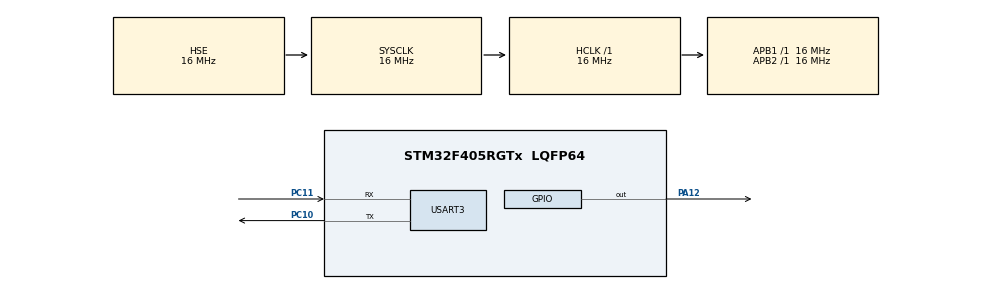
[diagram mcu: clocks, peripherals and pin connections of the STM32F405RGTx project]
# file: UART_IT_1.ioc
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Mcu.Family=STM32F4
Mcu.Name=STM32F405RGTx
Mcu.Package=LQFP64
NVIC.PriorityGroup=NVIC_PRIORITYGROUP_4
NVIC.USART3_IRQn=true\:0\:0\:false\:false\:true\:true\:true\:true
PA12.Signal=GPIO_Output
PA13.Mode=Serial_Wire
PA13.Signal=SYS_JTMS-SWDIO
PA14.Mode=Serial_Wire
PA14.Signal=SYS_JTCK-SWCLK
PC10.Mode=Asynchronous
PC10.Signal=USART3_TX
PC11.Mode=Asynchronous
PC11.Signal=USART3_RX
PH0-OSC_IN.Mode=HSE-External-Oscillator
PH0-OSC_IN.Signal=RCC_OSC_IN
PH1-OSC_OUT.Mode=HSE-External-Oscillator
PH1-OSC_OUT.Signal=RCC_OSC_OUT
ProjectManager.HeapSize=0x200
ProjectManager.StackSize=0x400
ProjectManager.TargetToolchain=MDK-ARM V5.32
RCC.AHBFreq_Value=16000000
RCC.APB1Freq_Value=16000000
RCC.APB2Freq_Value=16000000
RCC.CortexFreq_Value=16000000
RCC.HSE_VALUE=16000000
RCC.HSI_VALUE=16000000
RCC.LSE_VALUE=32768
RCC.PLLSourceVirtual=RCC_PLLSOURCE_HSE
RCC.SYSCLKFreq_VALUE=16000000
RCC.SYSCLKSource=RCC_SYSCLKSOURCE_HSE
RCC.VCOOutputFreq_Value=192000000
USART3.VirtualMode=VM_ASYNC
board=custom

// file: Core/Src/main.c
/* USER CODE BEGIN Header */
/**
  ******************************************************************************
  * @file           : main.c
  * @brief          : Main program body
  ******************************************************************************
  * @attention
  *
  * Copyright (c) 2023 STMicroelectronics.
  * All rights reserved.
  *
  * This software is licensed under terms that can be found in the LICENSE file
  * in the root directory of this software component.
  * If no LICENSE file comes with this software, it is provided AS-IS.
  *
  ******************************************************************************
  */
/* USER CODE END Header */
#include "main.h"

/* USER CODE BEGIN PM */
#define LED1_ON HAL_GPIO_TogglePin(GPIOA,GPIO_PIN_12)
/* USER CODE END PM */

UART_HandleTypeDef huart3;

void SystemClock_Config(void);
static void MX_GPIO_Init(void);
static void MX_USART3_UART_Init(void);

/* USER CODE BEGIN 0 */
  uint8_t data[2000];
	uint8_t count;
/* USER CODE END 0 */

	void HAL_UART_TxCpltCallback(UART_HandleTypeDef *huart)
{

}
int main(void)
{
  /* USER CODE BEGIN 1 */
{
for (int i=0; i<2000; i++)
 {
   data[i] = 'x';
 }
  /* USER CODE END 1 */

  /* MCU Configuration--------------------------------------------------------*/

  /* Reset of all peripherals, Initializes the Flash interface and the Systick. */
  HAL_Init();

  /* Configure the system clock */
  SystemClock_Config();

  /* Initialize all configured peripherals */
  MX_GPIO_Init();
  MX_USART3_UART_Init();

  /* Infinite loop */
  while (1)
  {

	LED1_ON;
  HAL_Delay (1000);

  count++;

  if ((count%20) == 0)
   {
     HAL_UART_Transmit_IT(&huart3, data, sizeof (data));
   }
  }
}
}

void SystemClock_Config(void)
{
  RCC_OscInitTypeDef RCC_OscInitStruct = {0};
  RCC_ClkInitTypeDef RCC_ClkInitStruct = {0};

  /** Configure the main internal regulator output voltage
  */
  __HAL_RCC_PWR_CLK_ENABLE();
  __HAL_PWR_VOLTAGESCALING_CONFIG(PWR_REGULATOR_VOLTAGE_SCALE1);

  /** Initializes the RCC Oscillators according to the specified parameters
  * in the RCC_OscInitTypeDef structure.
  */
  RCC_OscInitStruct.OscillatorType = RCC_OSCILLATORTYPE_HSE;
  RCC_OscInitStruct.HSEState = RCC_HSE_ON;
  RCC_OscInitStruct.PLL.PLLState = RCC_PLL_NONE;
  if (HAL_RCC_OscConfig(&RCC_OscInitStruct) != HAL_OK)
  {
    Error_Handler();
  }

  /** Initializes the CPU, AHB and APB buses clocks
  */
  RCC_ClkInitStruct.ClockType = RCC_CLOCKTYPE_HCLK|RCC_CLOCKTYPE_SYSCLK
                              |RCC_CLOCKTYPE_PCLK1|RCC_CLOCKTYPE_PCLK2;
  RCC_ClkInitStruct.SYSCLKSource = RCC_SYSCLKSOURCE_HSE;
  RCC_ClkInitStruct.AHBCLKDivider = RCC_SYSCLK_DIV1;
  RCC_ClkInitStruct.APB1CLKDivider = RCC_HCLK_DIV1;
  RCC_ClkInitStruct.APB2CLKDivider = RCC_HCLK_DIV1;

  if (HAL_RCC_ClockConfig(&RCC_ClkInitStruct, FLASH_LATENCY_0) != HAL_OK)
  {
    Error_Handler();
  }
}

static void MX_USART3_UART_Init(void)
{

  huart3.Instance = USART3;
  huart3.Init.BaudRate = 115200;
  huart3.Init.WordLength = UART_WORDLENGTH_8B;
  huart3.Init.StopBits = UART_STOPBITS_1;
  huart3.Init.Parity = UART_PARITY_NONE;
  huart3.Init.Mode = UART_MODE_TX_RX;
  huart3.Init.HwFlowCtl = UART_HWCONTROL_NONE;
  huart3.Init.OverSampling = UART_OVERSAMPLING_16;
  if (HAL_UART_Init(&huart3) != HAL_OK)
  {
    Error_Handler();
  }

}

static void MX_GPIO_Init(void)
{
  GPIO_InitTypeDef GPIO_InitStruct = {0};

  /* GPIO Ports Clock Enable */
  __HAL_RCC_GPIOH_CLK_ENABLE();
  __HAL_RCC_GPIOA_CLK_ENABLE();
  __HAL_RCC_GPIOC_CLK_ENABLE();

  /*Configure GPIO pin Output Level */
  HAL_GPIO_WritePin(GPIOA, GPIO_PIN_12, GPIO_PIN_RESET);

  /*Configure GPIO pin : PA12 */
  GPIO_InitStruct.Pin = GPIO_PIN_12;
  GPIO_InitStruct.Mode = GPIO_MODE_OUTPUT_PP;
  GPIO_InitStruct.Pull = GPIO_NOPULL;
  GPIO_InitStruct.Speed = GPIO_SPEED_FREQ_LOW;
  HAL_GPIO_Init(GPIOA, &GPIO_InitStruct);

}

void Error_Handler(void)
{
  __disable_irq();
  while (1)
  {
  }
}
